# ESP32-H4 register map
Vendor: ESPRESSIF SYSTEMS (SHANGHAI) CO., LTD.; Series: ESP32 H-Series; File version: 1
CPU: RV32IMAC r0p0, little endian, no MPU, no FPU, 0 interrupt priority bits
Address unit: 32 bits
Registers are 32-bit, read-write, reset 0x0 unless marked. A register's access mark holds for its fields unless they carry their own. Offsets are from the block's base; [hi:lo] are bit positions; {n}, {i} and the like mark numbered series.

## LP_IO_MUX — Low-power Input/Output Multiplexer
Base 0x600B3800
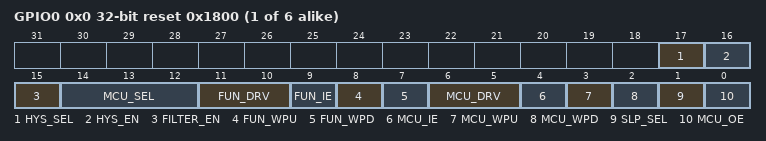
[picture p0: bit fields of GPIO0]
{0x0+4i} GPIO{i} (i=0..5) reset 0x1800 — LP IO MUX configuration register for LP_GPIO{i}
  [17] HYS_SEL — Configures to choose the signal for enabling the hysteresis function for LP_GPIO%s. \\ 0: Choose the output enable signal of eFuse\\ 1: Choose the output enable signal of LP_IO_MUX_GPIO%s_HYS_EN\\
  [16] HYS_EN — Configures whether or not to enable the hysteresis function of the pin when LP_IO_MUX_GPIO%s_HYS_SEL is set to 1.\\ 0: Disable\\ 1: Enable\\
  [15] FILTER_EN — Configures whether or not to enable filter for pin input signals.\\ 0: Disable\\ 1: Enable\\
  [14:12] MCU_SEL — Configures to select LP IO MUX function for this signal. \\ 0: Select Function 0\\ 1: Select Function 1\\ ......\\
  [11:10] FUN_DRV — Configures the drive strength of LP_GPIO%s. \\ 0: ~5 mA\\ 1: ~10 mA\\ 2: ~20 mA\\ 3: ~40 mA\\
  [9] FUN_IE — Configures whether or not to enable input of LP_GPIO%s.\\ 0: Disable\\ 1: Enable\\
  [8] FUN_WPU — Configures whether or not enable pull-up resistor of LP_GPIO%s.\\ 0: Disable\\ 1: Enable\\
  [7] FUN_WPD — Configures whether or not to enable pull-down resistor of LP_GPIO%s.\\ 0: Disable\\ 1: Enable\\
  [6:5] MCU_DRV — Configures the drive strength of LP_GPIO%s during sleep mode. \\ 0: ~5 mA\\ 1: ~10 mA\\ 2: ~20 mA\\ 3: ~40 mA\\
  [4] MCU_IE — Configures whether or not to enable the input of LP_GPIO%s during sleep mode.\\ 0: Disable\\ 1: Enable\\
  [3] MCU_WPU — Configures whether or not to enable pull-up resistor of LP_GPIO%s during sleep mode. \\ 0: Disable\\ 1: Enable\\
  [2] MCU_WPD — Configure whether or not to enable pull-down resistor of LP_GPIO%s in sleep mode.\\ 0: Disable\\ 1: Enable\\
  [1] SLP_SEL — Configures whether or not to enter sleep mode for LP_GPIO%s.\\ 0: Not enter\\ 1: Enter\\
  [0] MCU_OE — Configures whether or not to enable the output of LP_GPIO%s in sleep mode. 0: Disable\\ 1: Enable\\
0x1FC DATE reset 0x2405210 — Version control register
  [27:0] REG_DATE

## PAU — PAU Peripheral
Base 0x60020000
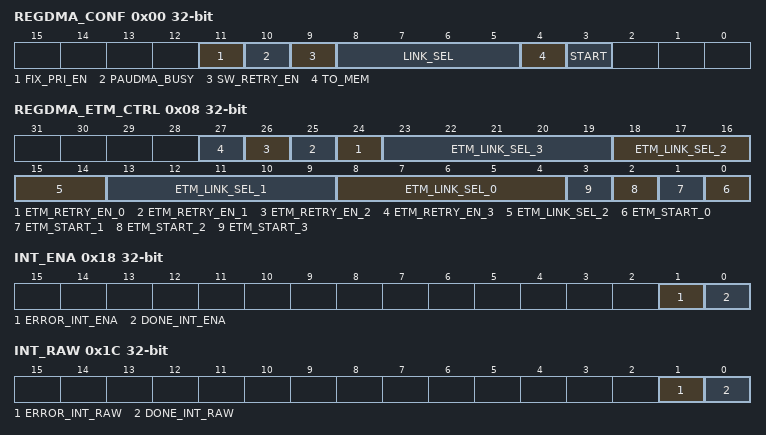
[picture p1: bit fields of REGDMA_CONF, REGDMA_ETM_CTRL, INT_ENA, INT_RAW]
0x00 REGDMA_CONF access per field — Peri backup control register
  [11] FIX_PRI_EN rw
  [10] PAUDMA_BUSY ro — regdma_busy
  [9] SW_RETRY_EN rw
  [8:5] LINK_SEL rw — Link select
  [4] TO_MEM rw — backup direction(reg to mem / mem to reg)
  [3] START wo — backup start signal
0x04 REGDMA_CLK_CONF — Clock control register
  [0] CLK_EN — clock enable
0x08 REGDMA_ETM_CTRL access per field — ETM start ctrl reg
  [n+24] ETM_RETRY_EN_{n} rw (n=0..3) — etm_retry
  [5n+8:5n+4] ETM_LINK_SEL_{n} rw (n=0..3) — etm_link sel
  [n] ETM_START_{n} wo (n=0..3) — etm_start_{n} reg
0x0C REGDMA_CURRENT_LINK_ADDR ro — current link addr
  [31:0] CURRENT_LINK_ADDR — current link addr reg
0x10 REGDMA_PERI_ADDR ro — Backup addr
  [31:0] PERI_ADDR — peri addr reg
0x14 REGDMA_MEM_ADDR ro — mem addr
  [31:0] MEM_ADDR — mem addr reg
0x18 INT_ENA — Read only register for error and done
  [1] ERROR_INT_ENA — error flag
  [0] DONE_INT_ENA — backup done flag
0x1C INT_RAW — Read only register for error and done
  [1] ERROR_INT_RAW — error flag
  [0] DONE_INT_RAW — backup done flag
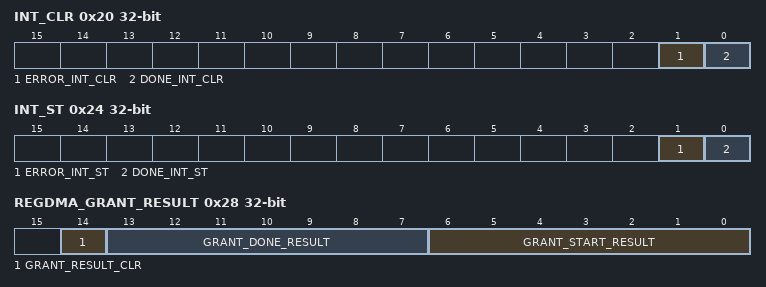
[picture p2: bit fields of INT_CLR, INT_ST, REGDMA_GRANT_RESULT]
0x20 INT_CLR wo — Read only register for error and done
  [1] ERROR_INT_CLR — error flag
  [0] DONE_INT_CLR — backup done flag
0x24 INT_ST ro — Read only register for error and done
  [1] ERROR_INT_ST — error flag
  [0] DONE_INT_ST — backup done flag
0x28 REGDMA_GRANT_RESULT access per field — Read only register for error and done
  [14] GRANT_RESULT_CLR wo — Grant result clear
  [13:7] GRANT_DONE_RESULT ro
  [6:0] GRANT_START_RESULT ro
0x3FC DATE reset 0x2404280
  [27:0] DATE — REGDMA date information/ REGDMA version information.
